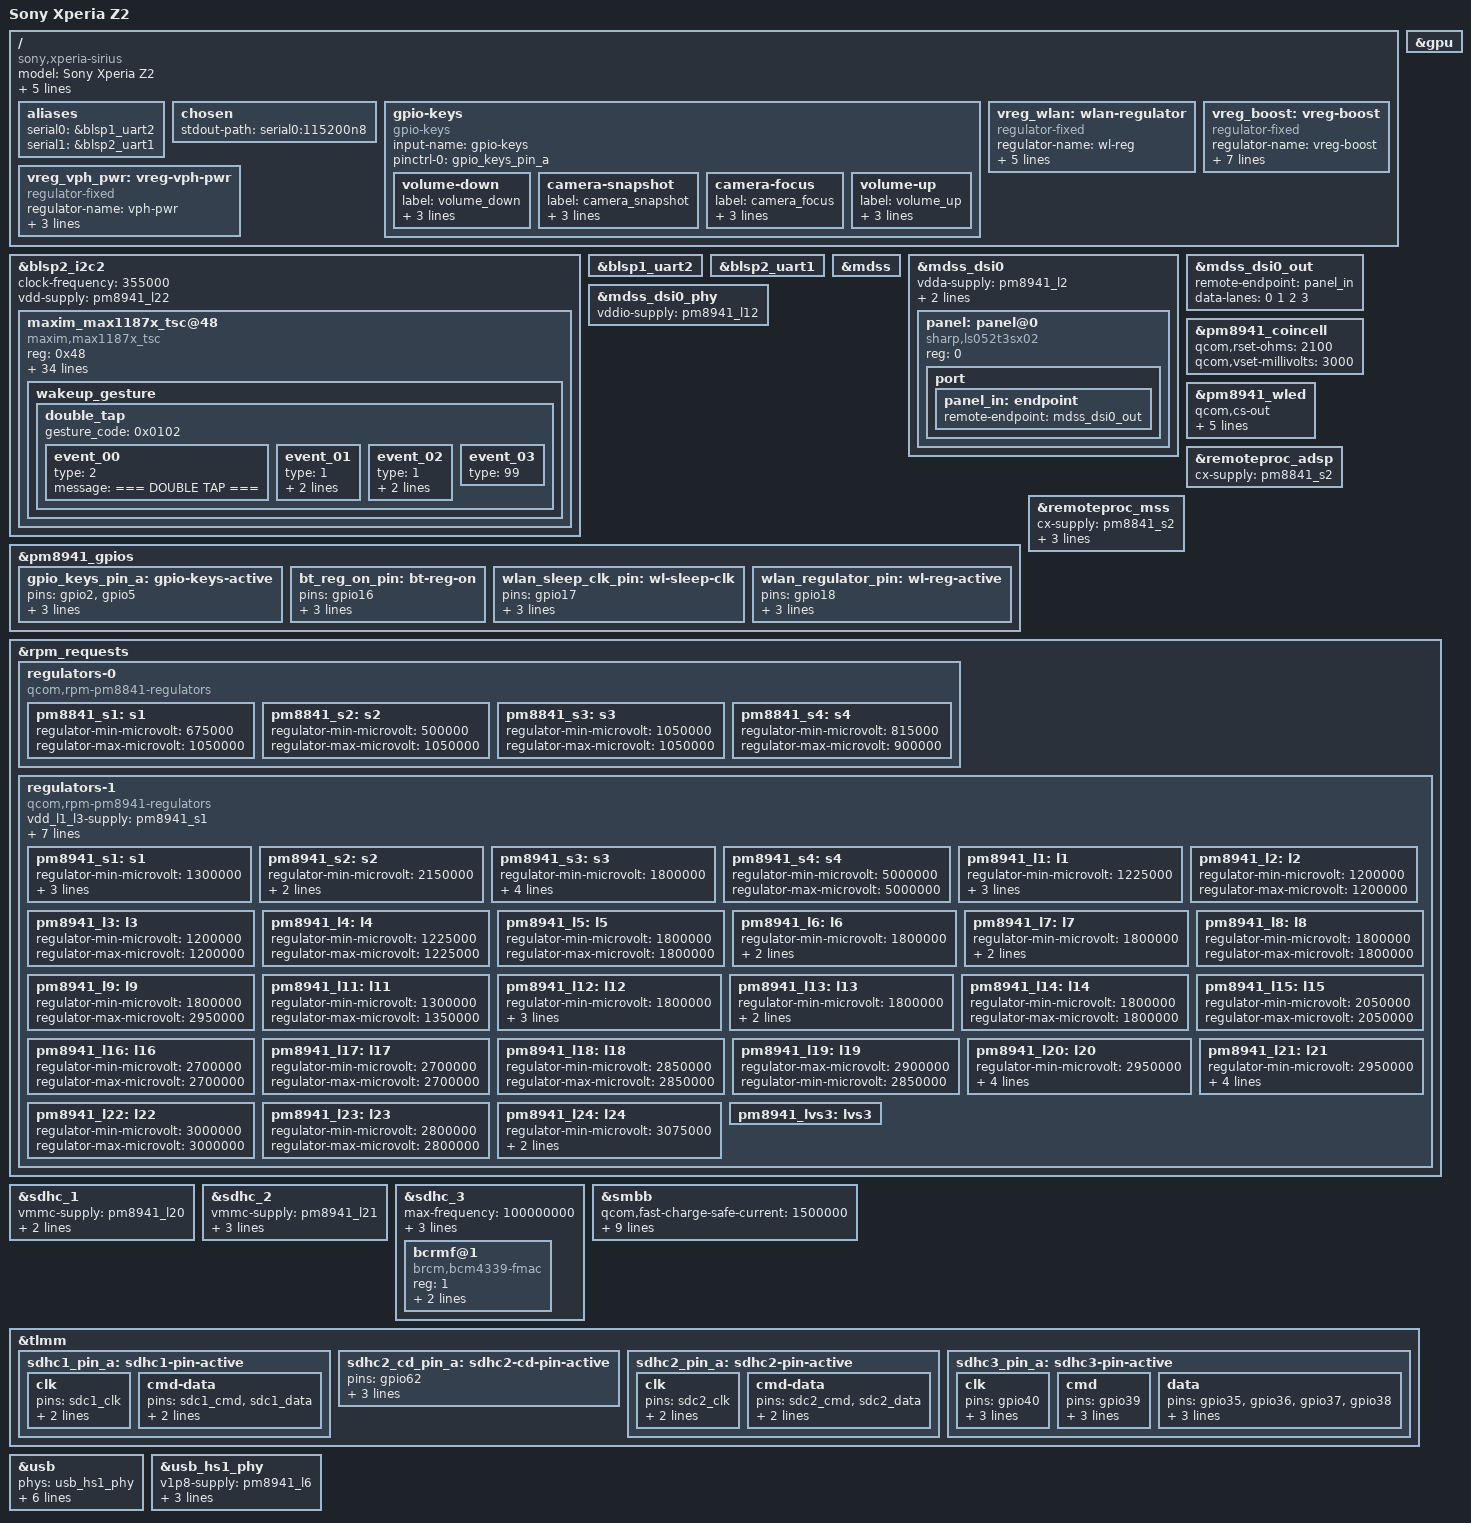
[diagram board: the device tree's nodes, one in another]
// SPDX-License-Identifier: GPL-2.0
#include "qcom-msm8974pro.dtsi"
#include "pm8841.dtsi"
#include "pm8941.dtsi"
#include "qcom-msm8974-sony-xperia-sirius-disp-hack.dtsi"
#include <dt-bindings/input/input.h>
#include <dt-bindings/pinctrl/qcom,pmic-gpio.h>

/ {
	model = "Sony Xperia Z2";
	compatible = "sony,xperia-sirius", "qcom,msm8974";
	somc,space-no = "1276-9754", "1278-9570";
	qcom,msm-id = <208 0x10000>,
		      <209 0x10000>,
		      <211 0x10000>,
		      <212 0x10000>,
		      <214 0x10000>,
		      <215 0x10000>,
		      <217 0x10000>,
		      <218 0x10000>;
	qcom,board-id = <0x8 0x0>;

	aliases {
		serial0 = &blsp1_uart2;
		serial1 = &blsp2_uart1;
	};

	chosen {
		stdout-path = "serial0:115200n8";
	};

	gpio-keys {
		compatible = "gpio-keys";
		input-name = "gpio-keys";

		pinctrl-names = "default";
		pinctrl-0 = <&gpio_keys_pin_a>;

		volume-down {
			label = "volume_down";
			gpios = <&pm8941_gpios 2 GPIO_ACTIVE_LOW>;
			linux,input-type = <1>;
			linux,code = <KEY_VOLUMEDOWN>;
		};

		camera-snapshot {
			label = "camera_snapshot";
			gpios = <&pm8941_gpios 3 GPIO_ACTIVE_LOW>;
			linux,input-type = <1>;
			linux,code = <KEY_CAMERA>;
		};

		camera-focus {
			label = "camera_focus";
			gpios = <&pm8941_gpios 4 GPIO_ACTIVE_LOW>;
			linux,input-type = <1>;
			linux,code = <KEY_CAMERA_FOCUS>;
		};

		volume-up {
			label = "volume_up";
			gpios = <&pm8941_gpios 5 GPIO_ACTIVE_LOW>;
			linux,input-type = <1>;
			linux,code = <KEY_VOLUMEUP>;
		};
	};

	vreg_wlan: wlan-regulator {
		compatible = "regulator-fixed";

		regulator-name = "wl-reg";
		regulator-min-microvolt = <3300000>;
		regulator-max-microvolt = <3300000>;

		gpio = <&pm8941_gpios 18 GPIO_ACTIVE_HIGH>;
		enable-active-high;

		pinctrl-names = "default";
		pinctrl-0 = <&wlan_regulator_pin>;
	};

	vreg_boost: vreg-boost {
		compatible = "regulator-fixed";

		regulator-name = "vreg-boost";
		regulator-min-microvolt = <3150000>;
		regulator-max-microvolt = <3150000>;

		regulator-always-on;
		regulator-boot-on;

		gpio = <&pm8941_gpios 21 GPIO_ACTIVE_HIGH>;
		enable-active-high;

		pinctrl-names = "default";
		pinctrl-0 = <&boost_bypass_n_pin>;
	};

	vreg_vph_pwr: vreg-vph-pwr {
		compatible = "regulator-fixed";
		regulator-name = "vph-pwr";

		regulator-min-microvolt = <3600000>;
		regulator-max-microvolt = <3600000>;

		regulator-always-on;
	};
};

&blsp2_i2c2 {
	status = "okay";

	clock-frequency = <355000>;
	vdd-supply = <&pm8941_l22>;

	maxim_max1187x_tsc@48 {
		compatible = "maxim,max1187x_tsc";
		reg = <0x48>;
		interrupt-parent = <&tlmm>;
		interrupts = <86 0x2>;
		vdd-supply = <&pm8941_l22>;
		touch_vdd-supply_name = "vdd";
		tirq-gpio = <&tlmm 86 0x2>;
		reset-gpio = <&tlmm 85 0x2>;
		reset_l2h = <1>;
		enable_resume_por = <1>;
		defaults_allow = <0>;
		default_config_id = <0>;
		default_chip_id = <0>;
		fw_name = "touch_chip_id_0x%02x_config_id_0x%%04x.bin";
		i2c_words = <128>;
		coordinate_settings = <0x4>;
		panel_margin_xl = <0>;
		lcd_x = <1080>;
		panel_margin_xh = <0>;
		panel_margin_yl = <0>;
		lcd_y = <1920>;
		panel_margin_yh = <0>;
		num_sensor_x = <20>;
		num_sensor_y = <34>;
		button_code0 = <0>;
		button_code1 = <0>;
		button_code2 = <0>;
		button_code3 = <0>;
		touch_pressure_enabled = <1>;
		touch_size_enabled = <0>;
		touch_orientation_enabled = <0>;
		glove_enabled = <0>;
		report_pen_as_finger = <1>;
		wakeup_gesture_support = <1>;
		wakeup_gesture_timeout = <2000>;
		wakeup_gesture {
			double_tap {
				gesture_code = <0x0102>;
				event_00 {
					type = <2>; /* LOG */
					message = "=== DOUBLE TAP ===";
				};
				event_01 {
					type = <1>; /* KEY */
					code = <116>; /* KEY_POWER */
					down = <1>;
				};
				event_02 {
					type = <1>; /* KEY */
					code = <116>; /* KEY_POWER */
					down = <0>;
				};
				event_03 {
					type = <99>; /* END */
				};
			};
		};
	};
};

&blsp1_uart2 {
	status = "okay";
};

&blsp2_uart1 {
	status = "okay";

	/* TODO: bluetooth node */
};

&gpu {
	status = "okay";
};

&mdss {
	status = "okay";
};

&mdss_dsi0 {
	status = "okay";

	vdda-supply = <&pm8941_l2>;
	vdd-supply = <&pm8941_lvs3>;
	vddio-supply = <&pm8941_l12>;

	panel: panel@0 {
		reg = <0>;
		compatible = "sharp,ls052t3sx02";

		port {
			panel_in: endpoint {
				remote-endpoint = <&mdss_dsi0_out>;
			};
		};
	};
};

&mdss_dsi0_out {
	remote-endpoint = <&panel_in>;
	data-lanes = <0 1 2 3>;
};

&mdss_dsi0_phy {
	status = "okay";

	vddio-supply = <&pm8941_l12>;
};

&pm8941_coincell {
	status = "okay";
	qcom,rset-ohms = <2100>;
	qcom,vset-millivolts = <3000>;
};

&pm8941_gpios {
	gpio_keys_pin_a: gpio-keys-active {
		pins = "gpio2", "gpio5";
		function = "normal";

		bias-pull-up;
		power-source = <PM8941_GPIO_S3>;
	};

	bt_reg_on_pin: bt-reg-on {
		pins = "gpio16";
		function = "normal";

		output-low;
		power-source = <PM8941_GPIO_S3>;
	};

	wlan_sleep_clk_pin: wl-sleep-clk {
		pins = "gpio17";
		function = "func2";

		output-high;
		power-source = <PM8941_GPIO_S3>;
	};

	wlan_regulator_pin: wl-reg-active {
		pins = "gpio18";
		function = "normal";

		bias-disable;
		power-source = <PM8941_GPIO_S3>;
	};
};

&pm8941_wled {
	status = "okay";

	qcom,cs-out;
	qcom,current-limit = <20>;
	qcom,current-boost-limit = <805>;
	qcom,switching-freq = <1600>;
	qcom,ovp = <29>;
	qcom,num-strings = <2>;
};

&remoteproc_adsp {
	cx-supply = <&pm8841_s2>;
	status = "okay";
};

&remoteproc_mss {
	cx-supply = <&pm8841_s2>;
	mss-supply = <&pm8841_s3>;
	mx-supply = <&pm8841_s1>;
	pll-supply = <&pm8941_l12>;
	status = "okay";
};

&rpm_requests {
	regulators-0 {
		compatible = "qcom,rpm-pm8841-regulators";

		pm8841_s1: s1 {
			regulator-min-microvolt = <675000>;
			regulator-max-microvolt = <1050000>;
		};

		pm8841_s2: s2 {
			regulator-min-microvolt = <500000>;
			regulator-max-microvolt = <1050000>;
		};

		pm8841_s3: s3 {
			regulator-min-microvolt = <1050000>;
			regulator-max-microvolt = <1050000>;
		};

		pm8841_s4: s4 {
			regulator-min-microvolt = <815000>;
			regulator-max-microvolt = <900000>;
		};
	};

	regulators-1 {
		compatible = "qcom,rpm-pm8941-regulators";

		vdd_l1_l3-supply = <&pm8941_s1>;
		vdd_l2_lvs1_2_3-supply = <&pm8941_s3>;
		vdd_l4_l11-supply = <&pm8941_s1>;
		vdd_l5_l7-supply = <&pm8941_s2>;
		vdd_l6_l12_l14_l15-supply = <&pm8941_s2>;
		vdd_l9_l10_l17_l22-supply = <&vreg_boost>;
		vdd_l13_l20_l23_l24-supply = <&vreg_boost>;
		vdd_l21-supply = <&vreg_boost>;

		pm8941_s1: s1 {
			regulator-min-microvolt = <1300000>;
			regulator-max-microvolt = <1300000>;
			regulator-always-on;
			regulator-boot-on;
		};

		pm8941_s2: s2 {
			regulator-min-microvolt = <2150000>;
			regulator-max-microvolt = <2150000>;
			regulator-boot-on;
		};

		pm8941_s3: s3 {
			regulator-min-microvolt = <1800000>;
			regulator-max-microvolt = <1800000>;
			regulator-always-on;
			regulator-boot-on;

			regulator-system-load = <154000>;
		};

		pm8941_s4: s4 {
			regulator-min-microvolt = <5000000>;
			regulator-max-microvolt = <5000000>;
		};

		pm8941_l1: l1 {
			regulator-min-microvolt = <1225000>;
			regulator-max-microvolt = <1225000>;

			regulator-always-on;
			regulator-boot-on;
		};

		pm8941_l2: l2 {
			regulator-min-microvolt = <1200000>;
			regulator-max-microvolt = <1200000>;
		};

		pm8941_l3: l3 {
			regulator-min-microvolt = <1200000>;
			regulator-max-microvolt = <1200000>;
		};

		pm8941_l4: l4 {
			regulator-min-microvolt = <1225000>;
			regulator-max-microvolt = <1225000>;
		};

		pm8941_l5: l5 {
			regulator-min-microvolt = <1800000>;
			regulator-max-microvolt = <1800000>;
		};

		pm8941_l6: l6 {
			regulator-min-microvolt = <1800000>;
			regulator-max-microvolt = <1800000>;

			regulator-boot-on;
		};

		pm8941_l7: l7 {
			regulator-min-microvolt = <1800000>;
			regulator-max-microvolt = <1800000>;

			regulator-boot-on;
		};

		pm8941_l8: l8 {
			regulator-min-microvolt = <1800000>;
			regulator-max-microvolt = <1800000>;
		};

		pm8941_l9: l9 {
			regulator-min-microvolt = <1800000>;
			regulator-max-microvolt = <2950000>;
		};

		pm8941_l11: l11 {
			regulator-min-microvolt = <1300000>;
			regulator-max-microvolt = <1350000>;
		};

		pm8941_l12: l12 {
			regulator-min-microvolt = <1800000>;
			regulator-max-microvolt = <1800000>;

			regulator-always-on;
			regulator-boot-on;
		};

		pm8941_l13: l13 {
			regulator-min-microvolt = <1800000>;
			regulator-max-microvolt = <2950000>;

			regulator-boot-on;
		};

		pm8941_l14: l14 {
			regulator-min-microvolt = <1800000>;
			regulator-max-microvolt = <1800000>;
		};

		pm8941_l15: l15 {
			regulator-min-microvolt = <2050000>;
			regulator-max-microvolt = <2050000>;
		};

		pm8941_l16: l16 {
			regulator-min-microvolt = <2700000>;
			regulator-max-microvolt = <2700000>;
		};

		pm8941_l17: l17 {
			regulator-min-microvolt = <2700000>;
			regulator-max-microvolt = <2700000>;
		};

		pm8941_l18: l18 {
			regulator-min-microvolt = <2850000>;
			regulator-max-microvolt = <2850000>;
		};

		pm8941_l19: l19 {
			regulator-max-microvolt = <2900000>;
			regulator-min-microvolt = <2850000>;
		};

		pm8941_l20: l20 {
			regulator-min-microvolt = <2950000>;
			regulator-max-microvolt = <2950000>;

			regulator-boot-on;
			regulator-allow-set-load;
			regulator-system-load = <200000>;
		};

		pm8941_l21: l21 {
			regulator-min-microvolt = <2950000>;
			regulator-max-microvolt = <2950000>;

			regulator-boot-on;
			regulator-allow-set-load;
			regulator-system-load = <200000>;
		};

		pm8941_l22: l22 {
			regulator-min-microvolt = <3000000>;
			regulator-max-microvolt = <3000000>;
		};

		pm8941_l23: l23 {
			regulator-min-microvolt = <2800000>;
			regulator-max-microvolt = <2800000>;
		};

		pm8941_l24: l24 {
			regulator-min-microvolt = <3075000>;
			regulator-max-microvolt = <3075000>;

			regulator-boot-on;
		};

		pm8941_lvs3: lvs3 {};
	};
};

&sdhc_1 {
	status = "okay";

	vmmc-supply = <&pm8941_l20>;
	vqmmc-supply = <&pm8941_s3>;

	pinctrl-names = "default";
	pinctrl-0 = <&sdhc1_pin_a>;
};

&sdhc_2 {
	status = "okay";

	vmmc-supply = <&pm8941_l21>;
	vqmmc-supply = <&pm8941_l13>;

	cd-gpios = <&tlmm 62 GPIO_ACTIVE_LOW>;

	pinctrl-names = "default";
	pinctrl-0 = <&sdhc2_pin_a>, <&sdhc2_cd_pin_a>;
};

&sdhc_3 {
	status = "okay";

	max-frequency = <100000000>;
	non-removable;
	vmmc-supply = <&vreg_wlan>;

	pinctrl-names = "default";
	pinctrl-0 = <&sdhc3_pin_a>;

	bcrmf@1 {
		compatible = "brcm,bcm4339-fmac", "brcm,bcm4329-fmac";
		reg = <1>;

		brcm,drive-strength = <10>;

		pinctrl-names = "default";
		pinctrl-0 = <&wlan_sleep_clk_pin>;
	};
};

&smbb {
	qcom,fast-charge-safe-current = <1500000>;
	qcom,fast-charge-current-limit = <1500000>;
	qcom,dc-current-limit = <1800000>;
	qcom,fast-charge-safe-voltage = <4400000>;
	qcom,fast-charge-high-threshold-voltage = <4350000>;
	qcom,fast-charge-low-threshold-voltage = <3400000>;
	qcom,auto-recharge-threshold-voltage = <4200000>;
	qcom,minimum-input-voltage = <4300000>;
};

&tlmm {
	sdhc1_pin_a: sdhc1-pin-active {
		clk {
			pins = "sdc1_clk";
			drive-strength = <16>;
			bias-disable;
		};

		cmd-data {
			pins = "sdc1_cmd", "sdc1_data";
			drive-strength = <10>;
			bias-pull-up;
		};
	};

	sdhc2_cd_pin_a: sdhc2-cd-pin-active {
		pins = "gpio62";
		function = "gpio";

		drive-strength = <2>;
		bias-disable;
	 };

	sdhc2_pin_a: sdhc2-pin-active {
		clk {
			pins = "sdc2_clk";
			drive-strength = <6>;
			bias-disable;
		};

		cmd-data {
			pins = "sdc2_cmd", "sdc2_data";
			drive-strength = <6>;
			bias-pull-up;
		};
	};

	sdhc3_pin_a: sdhc3-pin-active {
		clk {
			pins = "gpio40";
			function = "sdc3";

			drive-strength = <10>;
			bias-disable;
		};

		cmd {
			pins = "gpio39";
			function = "sdc3";

			drive-strength = <10>;
			bias-pull-up;
		};

		data {
			pins = "gpio35", "gpio36", "gpio37", "gpio38";
			function = "sdc3";

			drive-strength = <10>;
			bias-pull-up;
		};
	};
};

&usb {
	phys = <&usb_hs1_phy>;
	phy-select = <&tcsr 0xb000 0>;
	extcon = <&smbb>, <&usb_id>;
	vbus-supply = <&chg_otg>;

	hnp-disable;
	srp-disable;
	adp-disable;

	status = "okay";
};

&usb_hs1_phy {
	v1p8-supply = <&pm8941_l6>;
	v3p3-supply = <&pm8941_l24>;

	extcon = <&smbb>;
	qcom,init-seq = /bits/ 8 <0x1 0x64>;

	status = "okay";
};
